# K1921VK01T register map
Vendor: NIIET; Series: K1921VKx; File version: 2.2
CPU: CM4 r0p1, little endian, MPU, FPU, 3 interrupt priority bits
Registers are 32-bit, read-write, reset 0x0 unless marked. A register's access mark holds for its fields unless they carry their own. Offsets are from the block's base; [hi:lo] are bit positions; {n}, {i} and the like mark numbered series; 'fields as' and 'values as' point back to an identical list.

## NT_PWM0 — PWM controller registers
Base 0xA000B000
Same registers: NT_PWM{n} {0xA000B000+0x1000*n} (n=1..8)
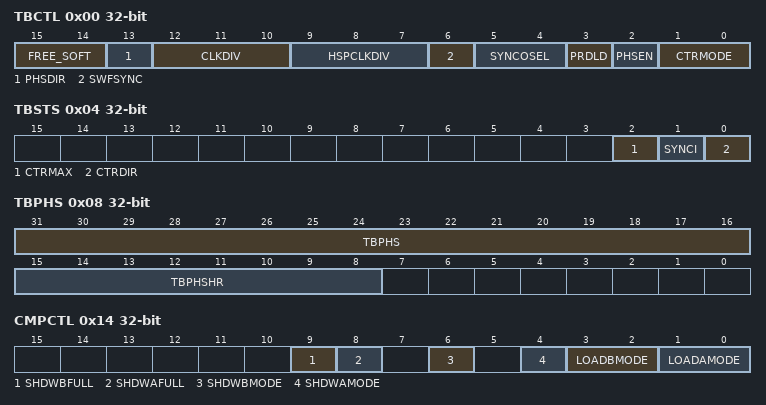
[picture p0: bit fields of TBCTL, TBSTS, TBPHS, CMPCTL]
0x00 TBCTL — Timer Control Register
  [15:14] FREE_SOFT
    0=StopAtTBCLK (stop timer at next TBCLK tact); 1=StopAtPeriod (stop timer when period ends)
  [13] PHSDIR — The phase direction
  [12:10] CLKDIV
    0=Div1 (clock not divided); 1=Div2 (clock divided by 2); 2=Div4 (clock divided by 4); 3=Div8 (clock divided by 8); 4=Div16 (clock divided by 16); 5=Div32 (clock divided by 32); 6=Div64 (clock divided by 64); 7=Div128 (clock divided by 128)
  [9:7] HSPCLKDIV
    0=Div1 (clock not divided); 1=Div2 (clock divided by 2); 2=Div4 (clock divided by 4); 3=Div6 (clock divided by 6); 4=Div8 (clock divided by 8); 5=Div10 (clock divided by 10); 6=Div12 (clock divided by 12); 7=Div14 (clock divided by 14)
  [6] SWFSYNC — Software emulation clock
  [5:4] SYNCOSEL
    0=SYNCI (PWM_SYNCI is source for PWM_SYNCO); 1=CTREqZero (CTR = 0000h is source for PWM_SYNCO); 2=CTREqCMPB (CTR = CMPB is source for PWM_SYNCO); 3=Disable (PWM_SYNCO generation disabled)
  [3] PRDLD — lazy loading mode register
  [2] PHSEN — load timer counter
  [1:0] CTRMODE
    0=Up (count direction up); 1=Down (count direction down); 2=UpDown (count direction up-down); 3=Stop (counter stopped)
0x04 TBSTS — Timer status register
  [2] CTRMAX ro — Position of the peak value
  [1] SYNCI — Synchronization status
  [0] CTRDIR — Current timer counting direction
0x08 TBPHS — register Phases
  [31:16] TBPHS, [15:8] TBPHSHR
0x0C TBCTR — Register current value of timer
  [15:0] TBCTR
0x10 TBPRD — Register maximum Timer
  [15:0] TBPRD
0x14 CMPCTL
  [9] SHDWBFULL ro — Status lazy loading in CMPB
  [8] SHDWAFULL ro — Status lazy loading in CMPA
  [6] SHDWBMODE — Write-permit mode
  [4] SHDWAMODE — Write-permit mode
  [3:2] LOADBMODE
    0=CTREqZero (shadow load for CMPx (x=A,B) when CTR = 0); 1=CTREqPRD (shadow load for CMPx (x=A,B) when CTR = PRD); 2=CTREqZeroPRD (shadow load for CMPx (x=A,B) when CTR = 0 or CTR = PRD); 3=Disable (shadow load for CMPx (x=A,B) disabled)
  [1:0] LOADAMODE
    values as LOADBMODE
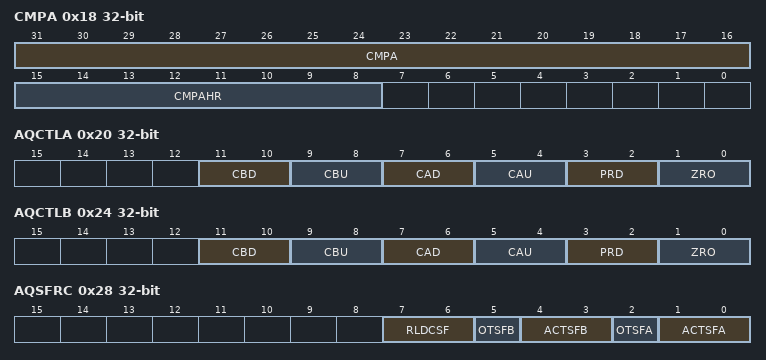
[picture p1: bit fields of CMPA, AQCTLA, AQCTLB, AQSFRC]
0x18 CMPA — Register threshold A
  [31:16] CMPA, [15:8] CMPAHR
0x1C CMPB — Register threshold B
  [31:16] CMPB
0x20 AQCTLA — Register handlers for output A
  [all] fields
    0=NoAction; 1=clear PWMA/PWMB; 2=Set (set PWMA/PWMB); 3=Toogle (inverse PWMA/PWMB)
  [11:10] CBD
  [9:8] CBU
  [7:6] CAD
  [5:4] CAU
  [3:2] PRD
  [1:0] ZRO
0x24 AQCTLB — Register handlers for output B
  fields as AQCTLA
0x28 AQSFRC — Register handlers for a single program management
  [7:6] RLDCSF
    0=CTREqZero (load when CTR = 0); 1=CTREqPRD (load when CTR = PRD); 2=CTREqZeroPRD (load when CTR = 0 or CTR = PRD); 3=NoShadow (load immediatelly)
  [5] OTSFB — Initialization single pulse
  [4:3] ACTSFB
    values as the fields of AQCTLA
  [2] OTSFA — Initialization single pulse
  [1:0] ACTSFA
    values as the fields of AQCTLA
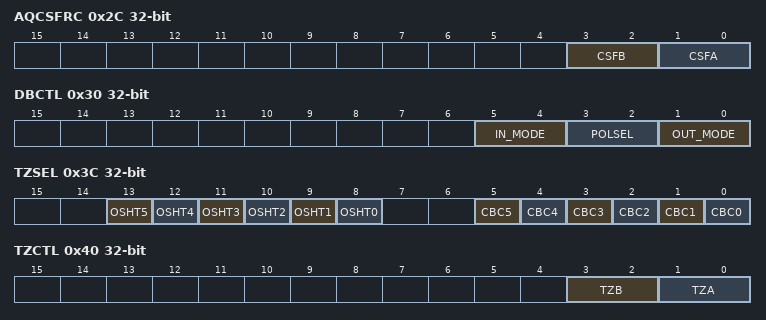
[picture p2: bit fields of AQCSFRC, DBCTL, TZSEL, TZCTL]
0x2C AQCSFRC — Register handlers for the cyclic program Management
  [3:2] CSFB
    0=NoAction; 1=clear PWMA/PWMB; 2=Set (set PWMA/PWMB)
  [1:0] CSFA
    0=NoAction; 1=clear PWMA/PWMB; 2=Set (set PWMA/PWMB)
0x30 DBCTL — Generator Control Register PWM Dead Time
  [5:4] IN_MODE
    0=APosNeg (PWMA is used for posedge and negedge control); 1=ANeg_BPos (PWMA is used for negedge and PWMB is used for posedge control); 2=APos_BNeg (PWMA is used for posedge and PWMB is used for negedge control); 3=BPosNeg (PWMB is used for posedge and negedge control)
  [3:2] POLSEL
    0=InvDisable (inverse disabled); 1=InvA (inverse on PWMA); 2=InvB (inverse on PWMB); 3=InvAB (inverse on PWMA and PWMB)
  [1:0] OUT_MODE
    0=NoSpec (edge for deadtime is no specified); 1=BNeg (deadtime on PWMB negedge); 2=APos (deadtime on PWMA posedge); 3=Apos_BNeg (deadtime on PWMA posedge and PWMB negedge)
0x34 DBRED — Dead time control register
  [9:0] DEL
0x38 DBFED — Dead time control register
  [9:0] DEL
0x3C TZSEL — Register the source of the accident
  [13] OSHT5 — source signal with the output of the accident Tzx(Single mode)
  [n+8] OSHT{n} (n=0..4)
  [5] CBC5 — source signal with the output of the accident Tzx(cyclic mode)
  [n] CBC{n} (n=0..4)
0x40 TZCTL — Control Register detector alarm signal
  [3:2] TZB
    0=Z (PWMA/PWMB go to Z on failture); 1=Set (PWMA/PWMB go to 1 on failture); 2=Clear (PWMA/PWMB go to 0 on failture); 3=no action on failture
  [1:0] TZA
    values as TZB
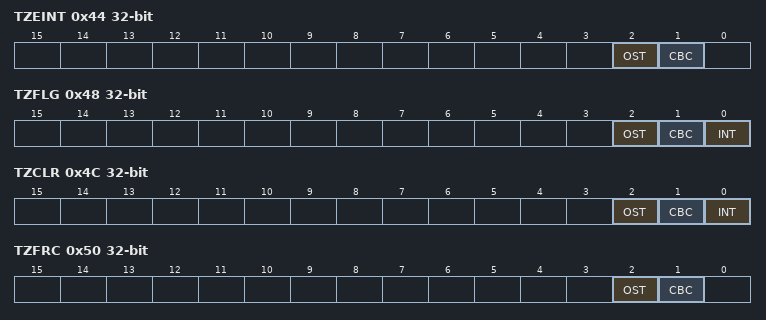
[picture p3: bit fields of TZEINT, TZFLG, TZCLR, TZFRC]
0x44 TZEINT — Interrupt mask register Signal Detection Alarms
  [2] OST — Interrupt generation(single mode)
  [1] CBC — Interrupt generation(cyclic mode)
0x48 TZFLG ro — Flags register interrupt signal detector Accidents
  [2] OST — Interrupt status in one-shot mode
  [1] CBC — Interrupt status in a cyclic mode
  [0] INT — Status of external interrupts NVIC
0x4C TZCLR — Register reset interrupt flag detector alarm signal
  [2] OST — Reset Interrupt status in one-shot mode
  [1] CBC — Reset Interrupt status in a cyclic mode
  [0] INT — Reset status of external interrupts NVIC
0x50 TZFRC — Register software emulation of faults
  [2] OST — Signal generation(single mode)
  [1] CBC — Signal generation(cyclic mode)
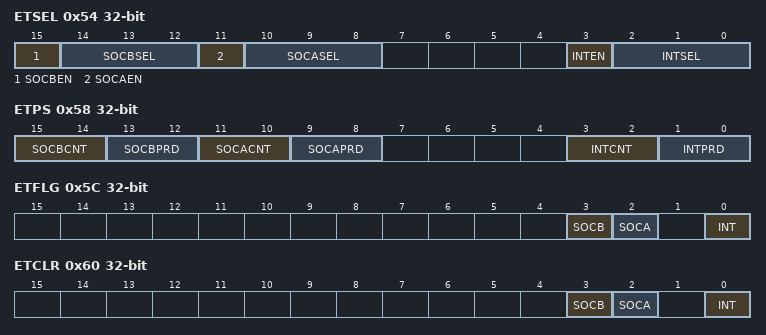
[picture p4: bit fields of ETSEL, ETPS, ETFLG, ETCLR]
0x54 ETSEL — A Source event trigger
  [15] SOCBEN — generation of an external signal (EPWMxSOCB)
  [14:12] SOCBSEL
    1=CTREqZero (generate PWM_SOCA/PWM_SOCB/PWN_INT impulse on CTR = 0); 2=CTREqPRD (generate PWM_SOCA/PWM_SOCB/PWN_INT impulse on CTR = PRD); 4=CTREqCMPA_OnUp (generate PWM_SOCA/PWM_SOCB/PWN_INT impulse on CTR = CMPA when count up); 5=CTREqCMPA_OnDown (generate PWM_SOCA/PWM_SOCB/PWN_INT impulse on CTR = CMPA when count down); 6=CTREqCMPB_OnUp (generate PWM_SOCA/PWM_SOCB/PWN_INT impulse on CTR = CMPB when count up); 7=CTREqCMPB_OnDown (generate PWM_SOCA/PWM_SOCB/PWN_INT impulse on CTR = CMPB when count down)
  [11] SOCAEN — generation of an external signal (EPWMxSOCA)
  [10:8] SOCASEL
    values as SOCBSEL
  [3] INTEN — Generation of external interrupt EPWMxINT
  [2:0] INTSEL
    values as SOCBSEL
0x58 ETPS — Prescaler register the event trigger
  [15:14] SOCBCNT ro, [13:12] SOCBPRD, [11:10] SOCACNT ro, [9:8] SOCAPRD, [3:2] INTCNT ro, [1:0] INTPRD
0x5C ETFLG ro — Register Flags event trigger
  [3] SOCB — Status of the external ADC EPWMxSOCB
  [2] SOCA — Status of the external ADC EPWMxSOCA
  [0] INT — Status of the external interrupt EPWMxINT
0x60 ETCLR — Register reset flags trigger events
  [3] SOCB — reset the status of the external ADC EPWMxSOCB
  [2] SOCA — reset the status of the external ADC EPWMxSOCA
  [0] INT — reset the status of the external interrupt EPWMxINT
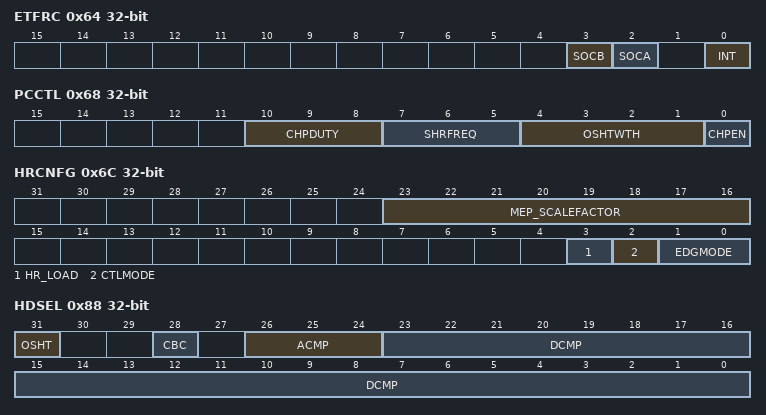
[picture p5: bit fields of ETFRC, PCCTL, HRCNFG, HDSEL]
0x64 ETFRC — Register software emulation events
  [3] SOCB — activation of the external ADC EPWMxSOCB
  [2] SOCA — activation of the external ADC EPWMxSOCA
  [0] INT — activation of an external interrupt EPWMxINT
0x68 PCCTL — Control Register modulator
  [10:8] CHPDUTY
    {v}=Duty_{v+1}_8 (v=0..6)
  [7:5] SHRFREQ
    {v}=Div{v+1} (sync frequency divide by {v+1}) (v=0..7)
  [4:1] OSHTWTH
  [0] CHPEN — enables the Modulator
0x6C HRCNFG — Register Configuration Block PWM High Definition
  [23:16] MEP_SCALEFACTOR ro
  [3] HR_LOAD — load event of deferred value to the active register
  [2] CTLMODE — register specifies the delay
  [1:0] EDGMODE
    1=posedge will be delayed; 2=negedge will be delayed; 3=PosNeg (posedge and negedge will be delayed)
0x70 FWDTH — Register width filtering
  [7:0] FWDTH
0x88 HDSEL — Register source event retention
  [31] OSHT — Enable source ACMP/DCMP in single mode
  [28] CBC — Enable source ACMP/DCMP in circle mode
  [26:24] ACMP
  [23:0] DCMP
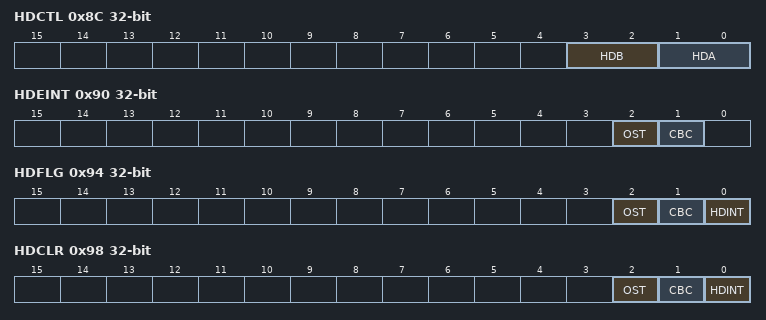
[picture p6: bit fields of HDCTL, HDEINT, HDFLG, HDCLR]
0x8C HDCTL — Control Register detector hold events
  [3:2] HDB
    1=Set (PWMA/PWMB go to 1 on failture); 2=Clear (PWMA/PWMB go to 0 on failture); 3=no action on failture
  [1:0] HDA
    values as HDB
0x90 HDEINT — Register software activation threshold trigger
  [2] OST — Activation threshold trigger in single mode
  [1] CBC — Activation threshold trigger in cycle mode
0x94 HDFLG ro — Registrer HD flag interrupt
  [2] OST — Activation threshold trigger in single mode
  [1] CBC — Activation threshold trigger in cycle mode
  [0] HDINT
0x98 HDCLR — Register clear HD flag
  [2] OST — Activation threshold trigger in single mode
  [1] CBC — Activation threshold trigger in cycle mode
  [0] HDINT — Clear flag HDINT
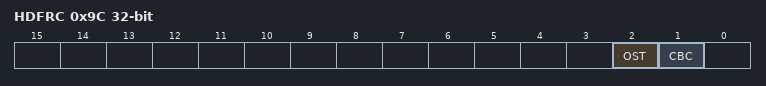
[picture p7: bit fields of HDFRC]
0x9C HDFRC — Register software activation threshold trigger
  [2] OST — activation threshold trigger in single mode
  [1] CBC — activation threshold trigger in cycle mode
0xA0 HDINTCLR wo — Register clear HD interrupt
  [0] HDINT — Clear HD interrupt
0xA4 TZINTCLR wo — Register clear TZ interrupt
  [0] TZINT — Clear TZ interrupt
0xA8 INTCLR wo — Register clear interrupt
  [0] INT — Clear interrupt
